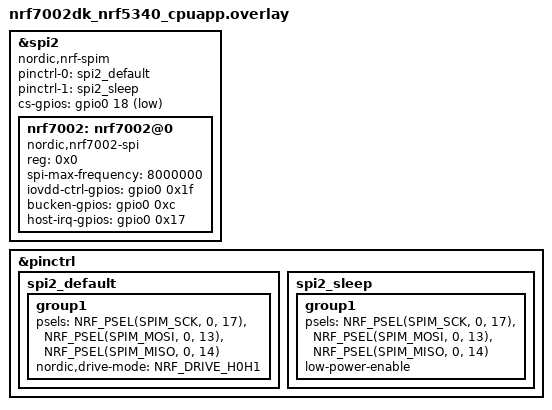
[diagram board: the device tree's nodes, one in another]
/* overlay file for app core */

/delete-node/ &qspi;

&spi2 {
	status = "okay"; 
	compatible = "nordic,nrf-spim";
	pinctrl-0 = <&spi2_default>;
	pinctrl-1 = <&spi2_sleep>;
	pinctrl-names = "default", "sleep";	
	cs-gpios = <&gpio0 18 GPIO_ACTIVE_LOW>;
	nrf7002: nrf7002@0 {
		status = "okay";
		compatible = "nordic,nrf7002-spi";
		reg = < 0x0 >;
		spi-max-frequency = < 8000000 >;		
		iovdd-ctrl-gpios = < &gpio0 0x1f 0x0 >;
		bucken-gpios = < &gpio0 0xc 0x0 >;
		host-irq-gpios = < &gpio0 0x17 0x0 >;
	};	
};

&pinctrl {
	spi2_default: spi2_default {
		group1 {
			psels = <NRF_PSEL(SPIM_SCK, 0, 17)>,
				<NRF_PSEL(SPIM_MOSI, 0, 13)>,
				<NRF_PSEL(SPIM_MISO, 0, 14)>;
			nordic,drive-mode = <NRF_DRIVE_H0H1>;
		};
	};

	spi2_sleep: spi2_sleep {
		group1 {
			psels = <NRF_PSEL(SPIM_SCK, 0, 17)>,
				<NRF_PSEL(SPIM_MOSI, 0, 13)>,
				<NRF_PSEL(SPIM_MISO, 0, 14)>;
			low-power-enable;
		};
	};
};

